# MCASP_CFG_DSP register map
Vendor: Texas Instruments
Registers are 32-bit, read-write, reset 0x0 unless marked. A register's access mark holds for its fields unless they carry their own. Offsets are as the file gives them; [hi:lo] are bit positions; 'fields as' and 'values as' point back to an identical list.

## MCASP_CFG_DSP (part 2 of 2)
0x00 MCASP_PID ro reset not defined — Peripheral identification register
  [31:0] REVISION — IP revision
0x04 MCASP_SYSCONFIG access per field reset 0x2 — Power idle module configuration register.
  [1:0] IDLE_MODE rw — 0x0: Force-idle mode 0x1: No-idle mode 0x2: Smart-idle mode - default state 0x3: Reserved
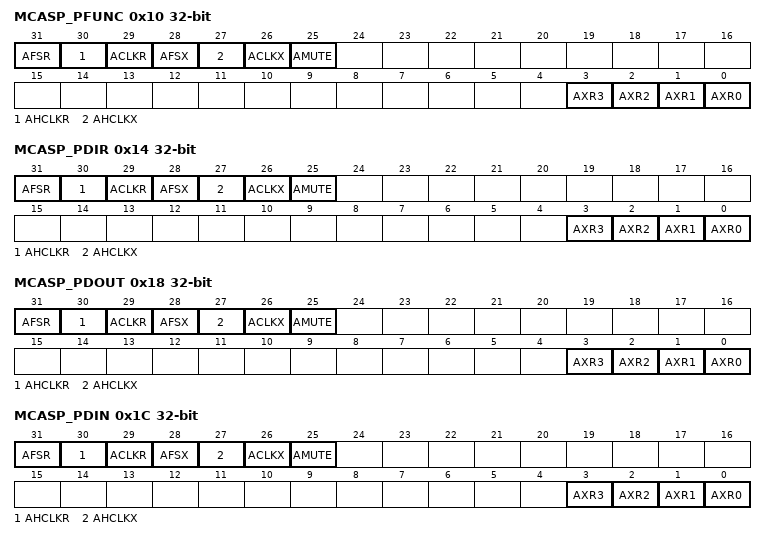
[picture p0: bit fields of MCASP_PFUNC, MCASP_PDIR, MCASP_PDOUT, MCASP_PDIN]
0x10 MCASP_PFUNC — Specifies the function of the pins as either a MCASP pin or a GPIO pin
  [31] AFSR — Determines if AFSR pin (device level abemcasp_afsr signal) functions as MCASP or GPIO.
    0=Pin_functions_as_MCASP_pin; 1=Pin_functions_as_GIO_pin
  [30] AHCLKR — Determines if AHCLKR pin (device level abemcasp_ahclkr signal) functions as MCASP or GPIO.
    0=Pin_functions_as_MCASP_pin; 1=Pin_functions_as_GIO_pin
  [29] ACLKR — Determines if ACLKR pin (device level abemcasp_aclkr signal) functions as MCASP or GPIO.
    0=Pin_functions_as_MCASP_pin; 1=Pin_functions_as_GIO_pin
  [28] AFSX — Determines if AFSX pin (device level abemcasp_afsx signal) functions as MCASP or GPIO.
    0=GPIO (Pin functions as MCASP pin); 1=Pin_functions_as_GIO_pin
  [27] AHCLKX — Determines if AHCLKX pin (device level abemcasp_ahclkx signal) functions as MCASP or GPIO.
    values as AFSX
  [26] ACLKX — Determines if ACLKX pin (device level abemcasp_aclkx signal) functions as MCASP or GPIO.
    values as AFSX
  [25] AMUTE — Determines if AMUTE pin (device level abemcasp_amuteout signal) functions as MCASP or GPIO.
    values as AFSX
  [3] AXR3 — Determines if AXR3 pin (device level abemcasp_axr3 signal) functions as MCASP or GPIO.
    0=Pin_functions_as_MCASP_pin; 1=Pin_functions_as_GIO_pin
  [2] AXR2 — Determines if AXR2 pin (device level abemcasp_axr2 signal) functions as MCASP or GPIO.
    0=Pin_functions_as_MCASP_pin; 1=Pin_functions_as_GIO_pin
  [1] AXR1 — Determines if AXR1 pin (device level abemcasp_axr1 signal) functions as MCASP or GPIO.
    0=Pin_functions_as_MCASP_pin; 1=Pin_functions_as_GIO_pin
  [0] AXR0 — Determines if AXR0 pin (device level abemcasp_axr signal) functions as MCASP or GPIO.
    values as AFSX
0x14 MCASP_PDIR — Pin direction register - specifies the direction of the MCASP pins as either an input or an output pin.
  [31] AFSR — Determines if AFSR pin (device level abemcasp_afsr signal) functions as an input or output.
    0=Input; 1=Output
  [30] AHCLKR — Determines if AHCLKR pin (device level abemcasp_ahclkr signal) functions as an input or output.
    0=Input; 1=Output
  [29] ACLKR — Determines if ACLKR pin (device level abemcasp_aclkr signal) functions as an input or output.
    0=Input; 1=Output
  [28] AFSX — Determines if AFSX pin (device level abemcasp_afsx signal) functions as an input or output.
    0=OUTPUT (Input); 1=Output
  [27] AHCLKX — Determines if AHCLKX pin (device level abemcasp_ahclkx signal) functions as an input or output.
    0=OUTPUT (Input); 1=Output
  [26] ACLKX — Determines if ACLKX pin (device level abemcasp_aclkx signal) functions as an input or output.
    0=OUTPUT (Input); 1=Output
  [25] AMUTE — Determines if AMUTE pin (device level abemcasp_amuteout signal) functions as an input or output.
    0=OUTPUT (Input); 1=Output
  [3] AXR3 — Determines if AXR3 pin (device level abemcasp_axr3 signal) functions as an input or output.
    0=Input; 1=Output
  [2] AXR2 — Determines if AXR2 pin (device level abemcasp_axr2 signal) functions as an input or output.
    0=Input; 1=Output
  [1] AXR1 — Determines if AXR1 pin (device level abemcasp_axr1 signal) functions as an input or output.
    0=Input; 1=Output
  [0] AXR0 — Determines if AXR0 pin (device level abemcasp_axr signal) functions as an input or output.
    0=OUTPUT (Input); 1=Output
0x18 MCASP_PDOUT — Pin data output register - holds a value for data out at all times, and may be read back at all times. The value held by is not affected by writing to and . However, the data value in is driven out onto the MCASP pin only if the corresponding bit in is set to 1 (GPIO function) and the corresponding bit in is set to 1 (output).
  [31] AFSR — Determines drive on AFSR output pin when the correspondingMCASP_PFUNC[31] and MCASP_PDIR[31] bits are set to 1.
    0=The_pin_drives_low; 1=The_pin_drives_high
  [30] AHCLKR — Determines drive on AHCLKR output pin when the correspondingMCASP_PFUNC[30] and MCASP_PDIR[30] bits are set to 1.
    0=The_pin_drives_low; 1=The_pin_drives_high
  [29] ACLKR — Determines drive on ACLKR output pin when the correspondingMCASP_PFUNC[29] and MCASP_PDIR[29] bits are set to 1
    0=The_pin_drives_low; 1=The_pin_drives_high
  [28] AFSX — Determines drive on AFSX output pin when the correspondingMCASP_PFUNC[28] and MCASP_PDIR[28] bits are set to 1.
    0=DRV1 (The pin drives low.); 1=The_pin_drives_high
  [27] AHCLKX — Determines drive on AHCLKX output pin when the correspondingMCASP_PFUNC[27] and MCASP_PDIR[27] bits are set to 1.
    0=DRV1 (The pin drives low.); 1=The_pin_drives_high
  [26] ACLKX — Determines drive on ACLKX output pin when the correspondingMCASP_PFUNC[26] and MCASP_PDIR[26] bits are set to 1
    0=DRV1 (The pin drives low.); 1=The_pin_drives_high
  [25] AMUTE — Determines drive on AMUTE output pin when the correspondingMCASP_PFUNC[25] and MCASP_PDIR[25] bits are set to 1.
    0=DRV1 (The pin drives low.); 1=The_pin_drives_high
  [3] AXR3 — Determines drive on AXR3 output pin when the correspondingMCASP_PFUNC[3] and MCASP_PDIR[3] bits are set to 1.
    0=The_pin_drives_low; 1=The_pin_drives_high
  [2] AXR2 — Determines drive on AXR2 output pin when the correspondingMCASP_PFUNC[2] and MCASP_PDIR[2] bits are set to 1.
    0=The_pin_drives_low; 1=The_pin_drives_high
  [1] AXR1 — Determines drive on AXR1 output pin when the correspondingMCASP_PFUNC[1] and MCASP_PDIR[1] bits are set to 1.
    0=The_pin_drives_low; 1=The_pin_drives_high
  [0] AXR0 — Determines drive on AXR0 output pin when the correspondingMCASP_PFUNC[0] and MCASP_PDIR[0] bits are set to 1.
    0=DRV1 (The pin drives low.); 1=The_pin_drives_high
0x1C MCASP_PDIN ro — Pin data input register - holds the state of all the MCASP pins. allows reading the actual value of the pin, regardless of the state of and .
  [31] AFSR — Logic level on AFSR pin (device level abemcasp_afsr signal).
    0=Pin_is_logic_low; 1=Pin_is_logic_high
  [30] AHCLKR — Logic level on AHCLKR pin (device level abemcasp_ahclkr signal).
    0=Pin_is_logic_low; 1=Pin_is_logic_high
  [29] ACLKR — Logic level on ACLKR pin (device level abemcasp_aclkr signal).
    0=Pin_is_logic_low; 1=Pin_is_logic_high
  [28] AFSX — Logic level on AFSX pin (device level abemcasp_afsx signal).
    0=LOW (Pin is logic low.); 1=Pin_is_logic_high
  [27] AHCLKX — Logic level on AHCLKX pin (device level abemcasp_ahclkx signal).
    0=LOW (Pin is logic low.); 1=Pin_is_logic_high
  [26] ACLKX — Logic level on ACLKX pin (device level abemcasp_aclkx signal).
    0=LOW (Pin is logic low.); 1=Pin_is_logic_high
  [25] AMUTE — Logic level on AMUTE pin (device level abemcasp_amuteout signal).
    0=LOW (Pin is logic low.); 1=Pin_is_logic_high
  [3] AXR3 — Logic level on AXR3 pin (device level abemcasp_axr3 signal).
    0=Pin_is_logic_low; 1=Pin_is_logic_high
  [2] AXR2 — Logic level on AXR2 pin (device level abemcasp_axr2 signal).
    0=Pin_is_logic_low; 1=Pin_is_logic_high
  [1] AXR1 — Logic level on AXR1 pin (device level abemcasp_axr1 signal).
    0=Pin_is_logic_low; 1=Pin_is_logic_high
  [0] AXR0 — Logic level on AXR0 pin (device level abemcasp_axr signal).
    0=LOW (Pin is logic low.); 1=Pin_is_logic_high
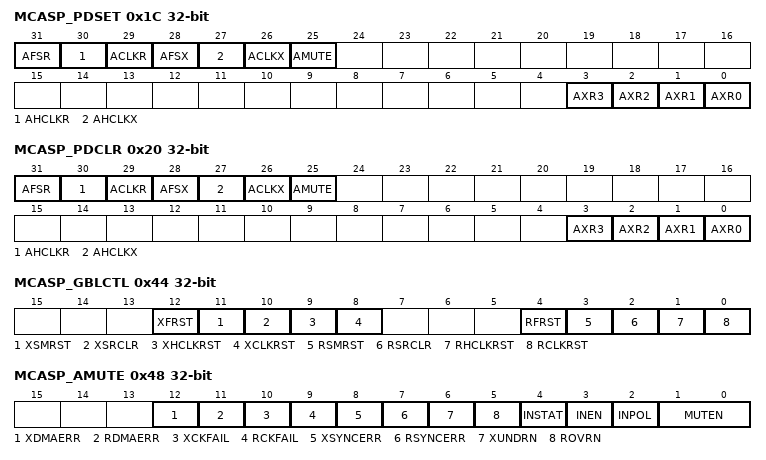
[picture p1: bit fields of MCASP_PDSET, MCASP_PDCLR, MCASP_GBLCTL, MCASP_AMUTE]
0x1C MCASP_PDSET wo — The pin data set register is an alias of the pin data output register () for writes only. Writing a 1 to the bit sets the corresponding bit in and, if = 1 (GPIO function) and = 1 (output), drives a logic high on the pin.
  [31] AFSR — Allows the corresponding AFSR bit inMCASP_PDOUT to be set to a logic high without affecting other I/O pins controlled by the same port.
    0=No_effect; 1=[31]_bit_is_set_to_1
  [30] AHCLKR — Allows the corresponding AHCLKR bit inMCASP_PDOUT to be set to a logic high without affecting other I/O pins controlled by the same port.
    0=No_effect; 1=[30]_bit_is_set_to_1
  [29] ACLKR — Allows the corresponding ACLKR bit inMCASP_PDOUT to be set to a logic high without affecting other I/O pins controlled by the same port.
    0=No_effect; 1=[29]_bit_is_set_to_1
  [28] AFSX — Allows the corresponding AFSX bit inMCASP_PDOUT to be set to a logic high without affecting other I/O pins controlled by the same port.
    0=SET (No effect); 1=[28]_bit_is_set_to_1
  [27] AHCLKX — Allows the corresponding AHCLKX bit inMCASP_PDOUT to be set to a logic high without affecting other I/O pins controlled by the same port.
    0=SET (No effect); 1=[27]_bit_is_set_to_1
  [26] ACLKX — Allows the corresponding ACLKX bit inMCASP_PDOUT to be set to a logic high without affecting other I/O pins controlled by the same port.
    0=SET (No effect); 1=[26]_bit_is_set_to_1
  [25] AMUTE — Allows the corresponding AMUTE bit inMCASP_PDOUT to be set to a logic high without affecting other I/O pins controlled by the same port.
    0=SET (No effect); 1=[25]_bit_is_set_to_1
  [3] AXR3 — Allows the AXR3 bit inMCASP_PDOUT to be set to a logic high without affecting other I/O pins controlled by the same port.
    0=No_effect; 1=[3]_bit_is_set_to_1
  [2] AXR2 — Allows the AXR2 bit inMCASP_PDOUT to be set to a logic high without affecting other I/O pins controlled by the same port.
    0=No_effect; 1=[2]_bit_is_set_to_1
  [1] AXR1 — Allows the AXR1 bit inMCASP_PDOUT to be set to a logic high without affecting other I/O pins controlled by the same port.
    0=No_effect; 1=[1]_bit_is_set_to_1
  [0] AXR0 — Allows the AXR0 bit inMCASP_PDOUT to be set to a logic high without affecting other I/O pins controlled by the same port.
    0=SET (No effect); 1=[0]_bit_is_set_to_1
0x20 MCASP_PDCLR — The pin data clear register is an alias of the pin data output register () for writes only. Writing a 1 to the bit clears the corresponding bit in and, if = 1 (GPIO function) and = 1 (output), drives a logic low on the pin.
  [31] AFSR — Allows the corresponding AFSR bit inMCASP_PDOUT to be cleared to a logic low without affecting other I/O pins controlled by the same port.
    0=No_effect; 1=[31]_bit_is_cleared_to_0
  [30] AHCLKR — Allows the corresponding AHCLKR bit inMCASP_PDOUT to be cleared to a logic low without affecting other I/O pins controlled by the same port.
    0=No_effect; 1=[30]_bit_is_cleared_to_0
  [29] ACLKR — Allows the corresponding ACLKR bit inMCASP_PDOUT to be cleared to a logic low without affecting other I/O pins controlled by the same port.
    0=No_effect; 1=[29]_bit_is_cleared_to_0
  [28] AFSX — Allows the corresponding AFSX bit inMCASP_PDOUT to be cleared to a logic low without affecting other I/O pins controlled by the same port.
    0=CLEAR (No effect); 1=[28]_bit_is_cleared_to_0
  [27] AHCLKX — Allows the corresponding AHCLKX bit inMCASP_PDOUT to be cleared to a logic low without affecting other I/O pins controlled by the same port.
    0=CLEAR (No effect); 1=[27]_bit_is_cleared_to_0
  [26] ACLKX — Allows the corresponding ACLKX bit inMCASP_PDOUT to be cleared to a logic low without affecting other I/O pins controlled by the same port.
    0=CLEAR (No effect); 1=[26]_bit_is_cleared_to_0
  [25] AMUTE — Allows the corresponding AMUTE bit inMCASP_PDOUT to be cleared to a logic low without affecting other I/O pins controlled by the same port.
    0=CLEAR (No effect); 1=[25]_bit_is_cleared_to_0
  [3] AXR3 — Allows the AXR3 bit inMCASP_PDOUT to be cleared to a logic low without affecting other I/O pins controlled by the same port.
    0=No_effect; 1=[3]_bit_is_cleared_to_0
  [2] AXR2 — Allows the AXR2 bit inMCASP_PDOUT to be cleared to a logic low without affecting other I/O pins controlled by the same port.
    0=No_effect; 1=[2]_bit_is_cleared_to_0
  [1] AXR1 — Allows the AXR1 bit inMCASP_PDOUT to be cleared to a logic low without affecting other I/O pins controlled by the same port.
    0=No_effect; 1=[1]_bit_is_cleared_to_0
  [0] AXR0 — Allows the AXR0 bit inMCASP_PDOUT to be cleared to a logic low without affecting other I/O pins controlled by the same port.
    0=CLEAR (No effect); 1=[0]_bit_is_cleared_to_0
0x44 MCASP_GBLCTL — Global transmit control register - provides initialization of the transmit and receive sections. The bit fields in are synchronized and latched by the transmitter and receiver corresponding clocks - abemcasp_aclkx clock ( bits [12:8] ) and abemcasp_aclkr ( bits [4:0] ), respectively. Before programming , ensure that the serial clocks are running. If the corresponding external serial clocks - abemcasp_clkx and abemcasp_aclkr, are not yet running, select the internal serial clock source in AHCLKXCTL, AHCLKRCTL, ACLKXCTL and ACLKRCTL before programming the . Also, after programming any bits in , do not proceed until reading back from and verifying that the bits in are latched.
  [12] XFRST — Transmit frame-sync generator reset enable bit
    0=RESET (The transmit frame-sync generator is reset.); 1=ACTIVE (The transmit frame-sync generator is active. When released from reset, the transmit frame-sync generator begins counting serial clocks and generating frame sync as programmed.)
  [11] XSMRST — Transmit state-machine reset enable bitAXR[n] pin state : If[n] = 0 and [n] = 1, the corresponding serializer [n] drives the AXR[n] pin to the state specified for inactive time slot. .
    0=RESET (The transmit state-machine is held in reset.); 1=ACTIVE (The transmit state-machine is released from reset. When released from reset, the transmit state-machine immediately transfers data from XBUF[n] to XRSR[n]. The transmit state-machine sets the underrun flag (XUNDRN) in MCASP_XSTAT, if XBUF[n] have not been preloaded with data before reset is released. The transmit state-machine also immediately begins detecting frame sync and is ready to transmit. Transmission of TDM time slot begins at slot 0 after reset is released.)
  [10] XSRCLR — Transmit serializer clear enable bit. By clearing and then setting this bit, the transmit buffer is flushed to an empty state (XDATA = 1). If XSMRST = 1, XSRCLR = 1, XDATA = 1, and XBUF is not loaded with new data before the start of the next active time slot, an underrun occurs.
    0=CLEAR (The transmit serializer is cleared.); 1=ACTIVE (The transmit serializer is active. When the transmit serializer is first taken out of reset (XSRCLR changes from 0 to 1), the transmit data ready bit (XDATA) in MCASP_XSTAT is set to indicate XBUF is ready to be written.)
  [9] XHCLKRST — Transmit high-frequency clock divider reset enable bit
    0=RESET (The transmitter high-frequency clock divider is held in reset.); 1=ACTIVE (The transmitter high-frequency clock divider is running.)
  [8] XCLKRST — Transmit clock divider reset enable bit
    0=RESET (The transmit clock divider is held in reset. When the clock divider is in reset, it passes through a divide-by-1 of its input.); 1=ACTIVE (The transmit clock divider is running.)
  [4] RFRST — Receive frame sync generator reset enable bit.
    0=RESET (Receive frame sync generator is reset.); 1=ACTIVE (Receive frame sync generator is active. When released from reset, the receive frame sync generator begins counting serial clocks and generating frame sync as programmed.)
  [3] RSMRST — Receive state machine reset enable bit.
    0=RESET (Receive state machine is held in reset.); 1=ACTIVE (Receive state machine is released from reset. When released from reset, the receive state machine immediately begins detecting frame sync and is ready to receive. Receive TDM time slot begins at slot 0 after reset is released.)
  [2] RSRCLR — Receive serializer clear enable bit. By clearing then setting this bit, the receive buffer is flushed.
    0=CLEAR (Receive serializers are cleared.); 1=ACTIVE (Receive serializers are active.)
  [1] RHCLKRST — Receive high-frequency clock divider reset enable bit.
    0=RESET (Receive high-frequency clock divider is held in reset.); 1=ACTIVE (Receive high-frequency clock divider is running.)
  [0] RCLKRST — Receive clock divider reset enable bit.
    0=RESET (Receive clock divider is held in reset. When the clock divider is in reset, it passes through a divide-by-1 of its input.); 1=ACTIVE (Receive clock divider is running.)
0x48 MCASP_AMUTE access per field — Mute control register - Controls the MCASP mute output pin - AMUTE (device level - abemcasp_amuteout signal)
  [12] XDMAERR rw — Drives AMUTE active enable bit on transmit DMA error (XDMAERR).
    0=ENABLE (Drive is disabled. Detection of transmit DMA error is ignored by abemcasp_amuteout.); 1=DMA_MUTEN_1 (Drive is enabled (active). Upon detection of transmit DMA error, abemcasp_amuteout is active and is driven according to MUTEN bits.)
  [11] RDMAERR rw — If receive DMA error (RDMAERR), drive AMUTE active enable bit.
    0=DMA_AMUTE._0 (Drive is disabled. Detection of receive DMA error is ignored by AMUTE.); 1=DMA_AMUTE_MUTEN_1 (Drive is enabled (active). Upon detection of receive DMA error, AMUTE is active and is driven according to MUTEN bit.)
  [10] XCKFAIL rw — XMT bad clock. Drives AMUTE active enable bit on transmit clock failure (XCKFAIL).
    0=ENABLE (Drive is disabled. Detection of transmit clock failure is ignored by abemcasp_amuteout.); 1=MUTEN_1 (Drive is enabled (active). Upon detection of transmit clock failure, abemcasp_amuteout is active and is driven according to MUTEN bits.)
  [9] RCKFAIL rw — If receive clock failure (RCKFAIL), drive AMUTE active enable bit.
    0=AMUTE._0 (Drive is disabled. Detection of receive clock failure is ignored by AMUTE.); 1=AMUTE_MUTEN_1 (Drive is enabled (active). Upon detection of receive clock failure, AMUTE is active and is driven according to MUTEN bit.)
  [8] XSYNCERR rw — XMT unexpected FS. Drives AMUTE active enable bit on unexpected transmit frame-sync error (XSYNCERR).
    0=ENABLE (Drive is disabled. Detection of unexpected transmit frame-sync error is ignored by abemcasp_amuteout.); 1=MUTEN_1 (Drive is enabled (active). Upon detection of unexpected transmit frame-sync error, abemcasp_amuteout is active and is driven according to MUTEN bit.)
  [7] RSYNCERR rw — If unexpected receive frame sync error (RSYNCERR), drive AMUTE active enable bit.
    0=AMUTE._0 (Drive is disabled. Detection of unexpected receive frame sync error is ignored by AMUTE.); 1=AMUTE_MUTEN_1 (Drive is enabled (active). Upon detection of unexpected receive frame sync error, AMUTE is active and is driven according to MUTEN bit.)
  [6] XUNDRN rw — XMT underrun occurs. Drives AMUTE active enable bit on ransmit underrun error (XUNDRN).
    0=ENABLE (Drive is disabled. Detection of transmit underrun error is ignored by abemcasp_amuteout.); 1=MUTEN_1 (Drive is enabled (active). Upon detection of transmit underrun error, abemcasp_amuteout is active and is driven according to MUTEN bit.)
  [5] ROVRN rw — If receiver overrun error (ROVRN), drive AMUTE active enable bit.
    0=AMUTE._0 (Drive is disabled. Detection of receiver overrun error is ignored by AMUTE.); 1=AMUTE_MUTEN_1 (Drive is enabled (active). Upon detection of receiver overrun error, AMUTE is active and is driven according to MUTEN bit.)
  [4] INSTAT ro — Status of mute in pin, determines drive on AXR[n] pin, when theMCASP_PFUNC[n] and MCASP_PDIR[n] bits are set to 1.
    0=ACTIVE (Inactive); 1=INSTAT_1_r (Active. Audio mute in error is detected.)
  [3] INEN rw — Drive the device level abemcasp_amuteout signal active when abemcasp_amutein error is active.
    0=ENABLE (Drive is disabled. abemcasp_amutein is ignored by abemcasp_amuteout.); 1=INSTAT_1 (Drive is enabled (active). INSTAT = 1 drives abemcasp_amuteout active.)
  [2] INPOL rw — Audio mute in - AMUTEIN pin (device level abemcasp_amutein signal) polarity select bit
    0=ACTLOW (Polarity is active high. A high on abemcasp_amutein sets INSTAT to 1.); 1=A_INSTAT_1 (Polarity is active low. A low on abemcasp_amutein sets INSTAT to 1.)
  [1:0] MUTEN rw — AMUTE pin (device level abemcasp_amuteout signal) enable bit field (unless overridden by GPIO registers)
    0=ERRLOW (Disabled, pin goes to 3-state condition.); 1=Pin is driven high if error is detected; 2=Pin_is_driven_low_if_error_is_detected
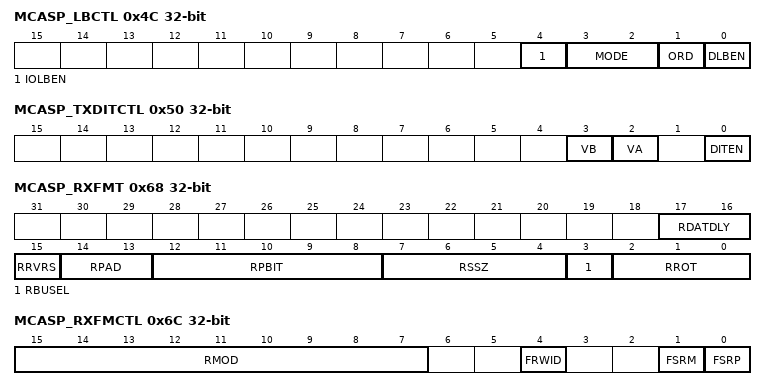
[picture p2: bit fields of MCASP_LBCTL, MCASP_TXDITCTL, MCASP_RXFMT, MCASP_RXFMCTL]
0x4C MCASP_LBCTL — The digital loopback control register () controls the internal (MCASP module)- level and chip-level loopback settings of the MCASP in TDM mode. Note that loopback is NOT supported if MCASP is configured in DIT mode.
  [4] IOLBEN — If DLBEN=0b1, the IOLBEN bit selects between and loopback modes. IOLBEN bit value is irrelevant, If DLBEN=0b0.
    0=INTERNAL_LB (MCASP internal loopback mode enabled. This selects a direct loopback between corresponding MCASP AXRn and AXRn+1 pins, bypassing device pad I/O buffers.); 1=CHIP_LB (Chip I/O-level loopback mode enabled. The MCASP data is looped back through the device pad I/O buffers.)
  [3:2] MODE — Loopback generator mode bits.0x2, 0x3: Reserved enum=RESERVED .
    0=NO_LOOPBACK (MODE must be set to 0x0 when MCASP is in non-loopback mode (DLBEN = 0b0)); 1=LOOPBACK (MODE must be set to 0x1 when MCASP operates in loopback mode (DLBEN =0b1). This is necessary to allow transmit clock and frame sync generators to be used by both transmit and receive sections.)
  [1] ORD — Loopback order bit when loopback mode is enabled (DLBEN = 1).
    0=ODD (Odd serializers N + 1 transmit to even serializers N that receive. The corresponding serializers must be programmed properly.); 1=EVEN (Even serializers N transmit to odd serializers N+1 that receive. The corresponding serializers must be programmed properly.)
  [0] DLBEN — Loop back mode.
    0=DISABLE (Loop back mode is disabled (normal MCASP operation).); 1=ENABLE (Loop back is enabled (TDM mode only). Loopback type is selected in IOLBEN bit.)
0x50 MCASP_TXDITCTL — Transmit DIT mode control register, controls DIT operations of the MCASP
  [3] VB — Valid bit for odd time slots (DIT right subframe).
    0=ONESTUFF (V bit is 0 during odd DIT subframes.); 1=V_bit_is_1_during_odd_DIT_subframes
  [2] VA — Valid bit for even time slots (DIT left subframe).
    0=ONESTUFF (V bit is 0 during even DIT subframes.); 1=V_bit_is_1_during_even_DIT_subframes
  [0] DITEN — DIT mode enable bit
    0=I2S (DIT mode is disabled.); 1=DIT (DIT mode is enabled. Transmitter operates in DIT encoded mode.)
0x64 MCASP_RXMASK — The receive format unit bit mask register () determines which bits of the received data are masked off and padded with a known value before being read by the CPU.
  [31:0] RMASK_31_0 — Receive data mask enable bit.
    0=USEMASK (Corresponding bit of receive data (after passing through reverse and rotate units) is masked out and then padded with the selected bit pad value (RPAD and RPBIT bits in RFMT).); 1=NOMASK (Corresponding bit of receive data (after passing through reverse and rotate units) is returned to CPU.)
0x68 MCASP_RXFMT — The receive bit stream format register () configures the receive data format.
  [17:16] RDATDLY — Receive Frame sync delay of AXR[n]
    0=0BIT (0-bit delay. The first receive data bit, AXR[n], occurs in same ACLKR cycle as the receive frame sync (AFSR).); 1=1BIT (1-bit delay. The first receive data bit, AXR[n], occurs one ACLKR cycle after the receive frame sync (AFSR).); 2=2BIT (2-bit delay. The first receive data bit, AXR[n], occurs two ACLKR cycles after the receive frame sync (AFSR).); 3=2BIT (Reserved)
  [15] RRVRS — Receive serial bitstream order
    0=LSBFIRST (Bitstream is LSB first. No bit reversal is performed in receive format bit reverse unit.); 1=MSBFIRST (Bitstream is MSB first. Bit reversal is performed in receive format bit reverse unit.)
  [14:13] RPAD — Pad value for extra bits in slot not belonging to the word. This field only applies to bits when RMASK[n] = 0.
    0=ZERO (Pad extra bits with 0.); 1=ONE (Pad extra bits with 1.); 2=RPBIT (Pad extra bits with one of the bits from the word as specified by RPBIT bits.); 3=RPBIT (Reserved)
  [12:8] RPBIT — RPBIT value determines which bit (as read by the CPU from RBUF[n]) is used to pad the extra bits. This field only applies when RPAD = 2h.0x01 - 0x1F: Pad with value of the bit positioned within the range RBUFn[31:1]. .
    0=Pad_with_value_of_bit_RBUFn[0]
  [7:4] RSSZ — Receive slot size.0x0 - 0x2 : Reserved enum=RSVD .
    3=8BITS (Slot size is 8 bits); 5=12BITS (Slot size is 12 bits); 7=16BITS (Slot size is 16 bits); 9=20BITS (Slot size is 20 bits); 11=24BITS (Slot size is 24 bits); 13=28BITS (Slot size is 28 bits); 14=32BITS (Reserved); 15=32BITS (Slot size is 32 bits)
  [3] RBUSEL — Selects whether reads from serializer buffer RBUF[n] originate from the peripheral configuration CFG port or the DATA port.
    0=VBUSP (Reads from XRBUF[n] originate on DATA port. Reads from XRBUF[n] on the peripheral configuration port are ignored.); 1=VBUS (Reads from XRBUF[n] originate on peripheral configuration port. Reads from XRBUF[n] on the DATA port are ignored.)
  [2:0] RROT — Right-rotation value for receive rotate right format unit.
    0=NONE (Rotate right by 0 (no rotation).); 1=4BITS (Rotate right by 4 bit positions.); 2=8BITS (Rotate right by 8 bit positions.); 3=12BITS (Rotate right by 12 bit positions.); 4=16BITS (Rotate right by 16 bit positions.); 5=20BITS (Rotate right by 20 bit positions.); 6=24BITS (Rotate right by 24 bit positions.); 7=28BITS (Rotate right by 28 bit positions.)
0x6C MCASP_RXFMCTL — The receive frame sync control register () configures the receive frame sync (AFSR).
  [15:7] RMOD — Receive frame sync mode select bits.0x0 - 0x1: Reserved . 0x3 - 0x20: 3-slot TDM to 32-slot TDM mode . 0x21 - 0x17F: Reserved . 0x181 - 0x1FF: Reserved .
    2=2-slot_TDM_mode(_I2S_receive_mode); 0x180=TDM_DIR_IC_DIR_MCASP)_384 (384-slot TDM (external DIR IC inputting 384-slot DIR frames to MCASP))
  [4] FRWID — Receive frame sync width select bit indicates the width of the receive frame sync (AFSR) during its active period.
    0=BIT (Single bit); 1=WORD (Single word)
  [1] FSRM — Receive frame sync generation select bit.
    0=EXTERNAL (Externally-generated receive frame sync); 1=INTERNAL (Internally-generated receive frame sync)
  [0] FSRP — Receive frame sync polarity select bit.
    0=RISINGEDGE (A rising edge on receive frame sync (AFSR) indicates the beginning of a frame.); 1=FALLINGEDGE (A falling edge on receive frame sync (AFSR) indicates the beginning of a frame.)
